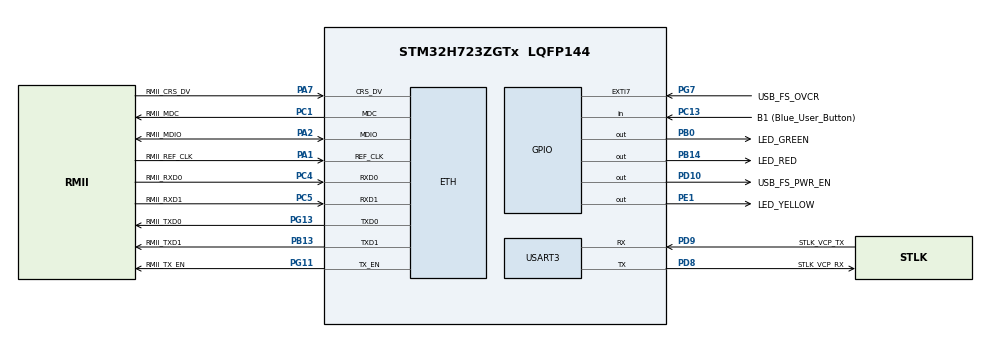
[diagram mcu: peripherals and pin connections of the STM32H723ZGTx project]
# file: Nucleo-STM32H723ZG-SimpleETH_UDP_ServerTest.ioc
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Mcu.Family=STM32H7
LWIP0.BSP.STBoard=false
PH0-OSC_IN.Signal=RCC_OSC_IN
RCC.CortexFreq_Value=520000000
RCC.HPRE=RCC_HCLK_DIV2
PB14.GPIO_Label=LED_RED
RCC.PLLFRACN=0
PA13(JTMS/SWDIO).Signal=DEBUG_JTMS-SWDIO
PB0.GPIO_Label=LED_GREEN
PC5.Mode=RMII
PC13.GPIO_Label=B1 (Blue_User_Button)
PB13.GPIO_Label=RMII_TXD1
PB13.Signal=ETH_TXD1
PG13.Signal=ETH_TXD0
PD9.Mode=Asynchronous
PG11.Signal=ETH_TX_EN
RCC.SYSCLKSource=RCC_SYSCLKSOURCE_PLLCLK
ProjectManager.StackSize=0x400
PA13(JTMS/SWDIO).Mode=Trace_Asynchronous_SW
USART3.VirtualMode-Asynchronous=VM_ASYNC
CORTEX_M7.Enable-Cortex_Memory_Protection_Unit_Region0_Settings=MPU_REGION_ENABLE
RCC.HCLKFreq_Value=260000000
PD8.Signal=USART3_TX
PE1.Signal=GPIO_Output
PB3(JTDO/TRACESWO).GPIO_Label=SWO
PH0-OSC_IN.Mode=HSE-External-Clock-Source
PH0-OSC_IN.GPIO_Label=MCO
LWIP.LWIP_RAM_HEAP_POINTER=0x30004000
RCC.HSE_VALUE=8000000
RCC.DIVM2=1
RCC.DIVM1=8
LWIP.MEM_SIZE=16360
PC14-OSC32_IN.Mode=LSE-External-Oscillator
PA14(JTCK/SWCLK).GPIO_Label=SWCLK
PC4.GPIO_Label=RMII_RXD0
PB3(JTDO/TRACESWO).Signal=DEBUG_JTDO-SWO
PA10.GPIO_Label=USB_FS_ID
PG13.Mode=RMII
LWIP0.BSP.solution=LAN8742
RCC.APB3Freq_Value=130000000
LWIP0.BSP.component=LAN8742
Mcu.Package=LQFP144
RCC.D1PPRE=RCC_APB3_DIV2
CORTEX_M7.BaseAddress-Cortex_Memory_Protection_Unit_Region1_Settings=0x30004000
PB3(JTDO/TRACESWO).Mode=Trace_Asynchronous_SW
PA2.GPIO_Label=RMII_MDIO
PA10.Signal=USB_OTG_HS_ID
CORTEX_M7.Size-Cortex_Memory_Protection_Unit_Region1_Settings=MPU_REGION_SIZE_16KB
RCC.APB4Freq_Value=130000000
ETH.RxBuffAddress=0x30000200
CORTEX_M7.Enable-Cortex_Memory_Protection_Unit_Region1_Settings=MPU_REGION_ENABLE
PA13(JTMS/SWDIO).GPIO_Label=SWDIO
PG11.GPIO_Label=RMII_TX_EN
PC5.Signal=ETH_RXD1
PB13.Mode=RMII
CORTEX_M7.IsShareable-Cortex_Memory_Protection_Unit_Region1_Settings=MPU_ACCESS_SHAREABLE
CORTEX_M7.IsBufferable-Cortex_Memory_Protection_Unit_Region0_Settings=MPU_ACCESS_BUFFERABLE
PC4.Mode=RMII
PC15-OSC32_OUT.Mode=LSE-External-Oscillator
CORTEX_M7.CPU_ICache=Enabled
RCC.DIVQ1=4
PA7.Mode=RMII
PG7.Signal=GPXTI7
LWIP0.BSP.i2caddr=0
PD9.GPIO_Label=STLK_VCP_TX
PC13.Signal=GPIO_Input
PA9.GPIO_Label=USB_FS_VBUS
PC4.Signal=ETH_RXD0
RCC.D2PPRE2=RCC_APB2_DIV2
RCC.D2PPRE1=RCC_APB1_DIV2
PD9.Signal=USART3_RX
RCC.DIVP1=1
PC14-OSC32_IN.Signal=RCC_OSC32_IN
PG13.GPIO_Label=RMII_TXD0
VP_LWIP_VS_Enabled.Mode=Enabled
PD8.GPIO_Label=STLK_VCP_RX
PD10.Signal=GPIO_Output
CORTEX_M7.MPU_Control=MPU_PRIVILEGED_DEFAULT
ProjectManager.TargetToolchain=STM32CubeIDE
CORTEX_M7.TypeExtField-Cortex_Memory_Protection_Unit_Region1_Settings=MPU_TEX_LEVEL1
LWIP.LWIP_SNTP=1
PA9.Signal=USB_OTG_HS_VBUS
RCC.DIVN2=19
RCC.DIVN1=65
CORTEX_M7.BaseAddress-Cortex_Memory_Protection_Unit_Region0_Settings=0x30000000
LWIP0.BSP.instance=LAN8742
RCC.USBFreq_Value=48000000
PD10.GPIO_Label=USB_FS_PWR_EN
LWIP0.BSP.api=BSP_COMPONENT_DRIVER
PD8.Mode=Asynchronous
PC15-OSC32_OUT.Signal=RCC_OSC32_OUT
PA1.Signal=ETH_REF_CLK
PB14.Signal=GPIO_Output
RCC.USBCLockSelection=RCC_USBCLKSOURCE_HSI48
board=NUCLEO-H723ZG
PE1.GPIO_Label=LED_YELLOW
RCC.APB2Freq_Value=130000000
PA1.Mode=RMII
PG7.GPIO_Label=USB_FS_OVCR
RCC.ADCFreq_Value=608000000
PA1.GPIO_Label=RMII_REF_CLK
PC1.GPIO_Label=RMII_MDC
CORTEX_M7.AccessPermission-Cortex_Memory_Protection_Unit_Region0_Settings=MPU_REGION_FULL_ACCESS
PH1-OSC_OUT.Signal=RCC_OSC_OUT
PA14(JTCK/SWCLK).Mode=Trace_Asynchronous_SW
Mcu.Name=STM32H723ZGTx
CORTEX_M7.Size-Cortex_Memory_Protection_Unit_Region0_Settings=MPU_REGION_SIZE_256B
PA2.Signal=ETH_MDIO
CORTEX_M7.AccessPermission-Cortex_Memory_Protection_Unit_Region1_Settings=MPU_REGION_FULL_ACCESS
RCC.SYSCLKFreq_VALUE=520000000
ETH.MediaInterface=HAL_ETH_RMII_MODE
PA7.GPIO_Label=RMII_CRS_DV
LWIP.BSP.number=1
PC5.GPIO_Label=RMII_RXD1
PG11.Mode=RMII
ProjectManager.HeapSize=0x200
LWIP.Version=v2.1.2_Cube
NVIC.PriorityGroup=NVIC_PRIORITYGROUP_4
PA2.Mode=RMII
RCC.D3PPRE=RCC_APB4_DIV2
PA14(JTCK/SWCLK).Signal=DEBUG_JTCK-SWCLK
ETH.RxDescAddress=0x30000000
CORTEX_M7.CPU_DCache=Enabled
LWIP0.BSP.name=Driver_PHY
RCC.APB1Freq_Value=130000000
PB0.Signal=GPIO_Output
PC1.Signal=ETH_MDC
PC1.Mode=RMII
PA7.Signal=ETH_CRS_DV
ETH.TxDescAddress=0x30000060

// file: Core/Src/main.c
/* USER CODE BEGIN Header */
/**
  ******************************************************************************
  * @file           : main.c
  * @brief          : Main program body
  ******************************************************************************
  * @attention
  *
  * <h2><center>&copy; Copyright (c) 2021 STMicroelectronics.
  * All rights reserved.</center></h2>
  *
  * This software component is licensed by ST under BSD 3-Clause license,
  * the "License"; You may not use this file except in compliance with the
  * License. You may obtain a copy of the License at:
  *                        opensource.org/licenses/BSD-3-Clause
  *
  ******************************************************************************
  */
/* USER CODE END Header */
#include "main.h"
#include "lwip.h"
#include "usart.h"
#include "gpio.h"

/* USER CODE BEGIN Includes */
#include "udp_server.h"
/* USER CODE END Includes */

void SystemClock_Config(void);
static void MPU_Config(void);

int main(void)
{

  /* MPU Configuration--------------------------------------------------------*/
  MPU_Config();

  /* Enable I-Cache---------------------------------------------------------*/
  SCB_EnableICache();

  /* Enable D-Cache---------------------------------------------------------*/
  SCB_EnableDCache();

  /* MCU Configuration--------------------------------------------------------*/

  /* Reset of all peripherals, Initializes the Flash interface and the Systick. */
  HAL_Init();

  /* Configure the system clock */
  SystemClock_Config();

  /* Initialize all configured peripherals */
  MX_GPIO_Init();
  MX_LWIP_Init();
  MX_USART3_UART_Init();
  /* USER CODE BEGIN 2 */
  SCB_CleanInvalidateDCache();

  //tcp_echoserver_init();
  UDPserverStart(7);   //Declared in ProjectFolder->LWIP->App->tcp_serverStMachine.c
  	  	  //My alls used function are there ProjectFolder->LWIP->App->tcp_serverStMachine.c

  uint32_t YellowLedTime=0;
  /* USER CODE END 2 */

  /* Infinite loop */
  /* USER CODE BEGIN WHILE */
  while (1)
  {
	  MX_LWIP_Process ();   //I don't use it its only for LwIP stack driver!
	  if(HAL_GetTick() - YellowLedTime > 200)
	  {
		  YellowLedTime=HAL_GetTick();
		  HAL_GPIO_TogglePin(LED_YELLOW_GPIO_Port, LED_YELLOW_Pin);
		  // HAL_UART_Transmit(&huart3,(uint8_t*) "HHH\n\r", sizeof("HHH\n\r")-1, 100);
	  }
    /* USER CODE END WHILE */

  }
}

void SystemClock_Config(void)
{
  RCC_OscInitTypeDef RCC_OscInitStruct = {0};
  RCC_ClkInitTypeDef RCC_ClkInitStruct = {0};

  /** Supply configuration update enable
  */
  HAL_PWREx_ConfigSupply(PWR_LDO_SUPPLY);
  /** Configure the main internal regulator output voltage
  */
  __HAL_PWR_VOLTAGESCALING_CONFIG(PWR_REGULATOR_VOLTAGE_SCALE0);

  while(!__HAL_PWR_GET_FLAG(PWR_FLAG_VOSRDY)) {}
  /** Initializes the RCC Oscillators according to the specified parameters
  * in the RCC_OscInitTypeDef structure.
  */
  RCC_OscInitStruct.OscillatorType = RCC_OSCILLATORTYPE_HSI;
  RCC_OscInitStruct.HSIState = RCC_HSI_DIV1;
  RCC_OscInitStruct.HSICalibrationValue = RCC_HSICALIBRATION_DEFAULT;
  RCC_OscInitStruct.PLL.PLLState = RCC_PLL_ON;
  RCC_OscInitStruct.PLL.PLLSource = RCC_PLLSOURCE_HSI;
  RCC_OscInitStruct.PLL.PLLM = 8;
  RCC_OscInitStruct.PLL.PLLN = 65;
  RCC_OscInitStruct.PLL.PLLP = 1;
  RCC_OscInitStruct.PLL.PLLQ = 4;
  RCC_OscInitStruct.PLL.PLLR = 2;
  RCC_OscInitStruct.PLL.PLLRGE = RCC_PLL1VCIRANGE_3;
  RCC_OscInitStruct.PLL.PLLVCOSEL = RCC_PLL1VCOWIDE;
  RCC_OscInitStruct.PLL.PLLFRACN = 0;
  if (HAL_RCC_OscConfig(&RCC_OscInitStruct) != HAL_OK)
  {
    Error_Handler();
  }
  /** Initializes the CPU, AHB and APB buses clocks
  */
  RCC_ClkInitStruct.ClockType = RCC_CLOCKTYPE_HCLK|RCC_CLOCKTYPE_SYSCLK
                              |RCC_CLOCKTYPE_PCLK1|RCC_CLOCKTYPE_PCLK2
                              |RCC_CLOCKTYPE_D3PCLK1|RCC_CLOCKTYPE_D1PCLK1;
  RCC_ClkInitStruct.SYSCLKSource = RCC_SYSCLKSOURCE_PLLCLK;
  RCC_ClkInitStruct.SYSCLKDivider = RCC_SYSCLK_DIV1;
  RCC_ClkInitStruct.AHBCLKDivider = RCC_HCLK_DIV2;
  RCC_ClkInitStruct.APB3CLKDivider = RCC_APB3_DIV2;
  RCC_ClkInitStruct.APB1CLKDivider = RCC_APB1_DIV2;
  RCC_ClkInitStruct.APB2CLKDivider = RCC_APB2_DIV2;
  RCC_ClkInitStruct.APB4CLKDivider = RCC_APB4_DIV2;

  if (HAL_RCC_ClockConfig(&RCC_ClkInitStruct, FLASH_LATENCY_3) != HAL_OK)
  {
    Error_Handler();
  }
}

/* MPU Configuration */

void MPU_Config(void)
{
  MPU_Region_InitTypeDef MPU_InitStruct = {0};

  /* Disables the MPU */
  HAL_MPU_Disable();
  /** Initializes and configures the Region and the memory to be protected
  */
  MPU_InitStruct.Enable = MPU_REGION_ENABLE;
  MPU_InitStruct.Number = MPU_REGION_NUMBER0;
  MPU_InitStruct.BaseAddress = 0x30000000;
  MPU_InitStruct.Size = MPU_REGION_SIZE_256B;
  MPU_InitStruct.SubRegionDisable = 0x0;
  MPU_InitStruct.TypeExtField = MPU_TEX_LEVEL0;
  MPU_InitStruct.AccessPermission = MPU_REGION_FULL_ACCESS;
  MPU_InitStruct.DisableExec = MPU_INSTRUCTION_ACCESS_ENABLE;
  MPU_InitStruct.IsShareable = MPU_ACCESS_NOT_SHAREABLE;
  MPU_InitStruct.IsCacheable = MPU_ACCESS_NOT_CACHEABLE;
  MPU_InitStruct.IsBufferable = MPU_ACCESS_BUFFERABLE;

  HAL_MPU_ConfigRegion(&MPU_InitStruct);
  /** Initializes and configures the Region and the memory to be protected
  */
  MPU_InitStruct.Number = MPU_REGION_NUMBER1;
  MPU_InitStruct.BaseAddress = 0x30004000;
  MPU_InitStruct.Size = MPU_REGION_SIZE_16KB;
  MPU_InitStruct.TypeExtField = MPU_TEX_LEVEL1;
  MPU_InitStruct.IsShareable = MPU_ACCESS_SHAREABLE;
  MPU_InitStruct.IsBufferable = MPU_ACCESS_NOT_BUFFERABLE;

  HAL_MPU_ConfigRegion(&MPU_InitStruct);
  /* Enables the MPU */
  HAL_MPU_Enable(MPU_PRIVILEGED_DEFAULT);

}

void Error_Handler(void)
{
  __disable_irq();
  while (1)
  {
  }
}

/************************ (C) COPYRIGHT STMicroelectronics *****END OF FILE****/
